# PIC16F1503 register map
Vendor: Microchip
Registers are 8-bit, read-write, no defined reset value unless marked. A register's access mark holds for its fields unless they carry their own. Addresses are absolute, and some are shared; only a register's first bit layout is shown; [hi:lo] are bit positions; {n}, {i} and the like mark numbered series.

## SFR
0x00 INDF0 — (power-on value xxxxxxxx)
0x01 INDF1 — (power-on value xxxxxxxx)
0x02 PCL reset 0x0
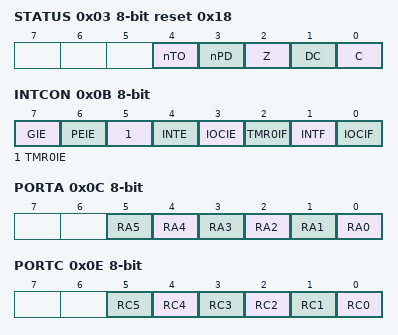
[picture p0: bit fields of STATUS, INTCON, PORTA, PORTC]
0x03 STATUS reset 0x18
  [4] nTO ro, [3] nPD ro, [2] Z, [1] DC, [0] C
0x04 FSR0L reset 0x0
0x05 FSR0H reset 0x0
0x06 FSR1L reset 0x0
0x07 FSR1H reset 0x0
0x08 BSR reset 0x0
  [4:0] BSR
0x09 WREG reset 0x0
  [7:0] WREG0
0x0A PCLATH reset 0x0
  [6:0] PCLATH
0x0B INTCON — (power-on value 0000000x)
  [7] GIE, [6] PEIE, [5] TMR0IE, [4] INTE, [3] IOCIE, [2] TMR0IF, [1] INTF, [0] IOCIF ro
0x0C PORTA — (power-on value --xxxxxx)
  [n] RA{n} (n=0..5)
0x0E PORTC — (power-on value --xxxxxx)
  [n] RC{n} (n=0..5)
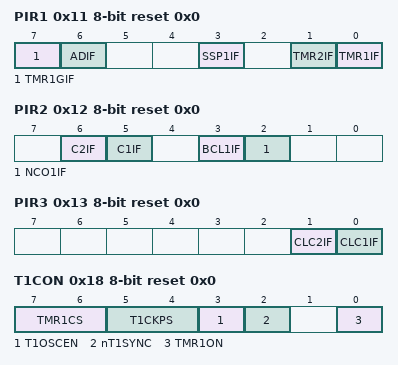
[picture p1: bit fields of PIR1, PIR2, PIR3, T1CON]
0x11 PIR1 reset 0x0
  [7] TMR1GIF — Timer1 Gate Interrupt Flag bit
  [6] ADIF — A/D Converter Interrupt Flag bit
  [3] SSP1IF
  [1] TMR2IF — TMR2 to PR2 Match Interrupt Flag bit
  [0] TMR1IF — TMR1 Overflow Interrupt Flag bit
0x12 PIR2 reset 0x0
  [6] C2IF, [5] C1IF, [3] BCL1IF, [2] NCO1IF
0x13 PIR3 reset 0x0
  [1] CLC2IF, [0] CLC1IF
0x15 TMR0 — (power-on value xxxxxxxx)
0x16 TMR1L — (power-on value xxxxxxxx)
0x17 TMR1H — (power-on value xxxxxxxx)
0x18 T1CON reset 0x0
  [7:6] TMR1CS, [5:4] T1CKPS, [3] T1OSCEN, [2] nT1SYNC, [0] TMR1ON
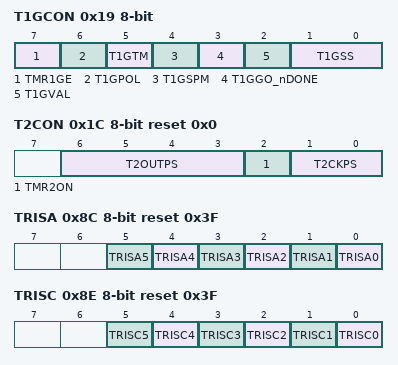
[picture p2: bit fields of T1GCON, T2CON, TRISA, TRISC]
0x19 T1GCON — (power-on value 00000x00)
  [7] TMR1GE, [6] T1GPOL, [5] T1GTM, [4] T1GSPM, [3] T1GGO_nDONE, [2] T1GVAL ro, [1:0] T1GSS
0x1A TMR2 reset 0x0
0x1B PR2 reset 0xFF
0x1C T2CON reset 0x0
  [6:3] T2OUTPS, [2] TMR2ON, [1:0] T2CKPS
0x8C TRISA reset 0x3F — PORTA Data Direction Control Register
  [n] TRISA{n} (n=0..5)
0x8E TRISC reset 0x3F — PORTC Data Direction Control Register
  [n] TRISC{n} (n=0..5)
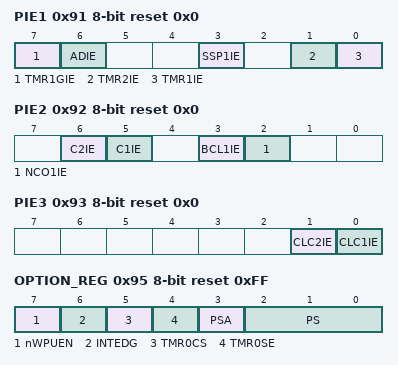
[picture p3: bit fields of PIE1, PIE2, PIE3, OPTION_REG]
0x91 PIE1 reset 0x0 — Peripheral Interrupt Enable Register 1
  [7] TMR1GIE — Timer1 Gate Interrupt Enable bit
  [6] ADIE — A/D Converter Interrupt Enable bit
  [3] SSP1IE
  [1] TMR2IE — TMR2 to PR2 Match Interrupt Enable bit
  [0] TMR1IE — TMR1 Overflow Interrupt Enable bit
0x92 PIE2 reset 0x0 — Peripheral Interrupt Enable Register 2
  [6] C2IE, [5] C1IE, [3] BCL1IE, [2] NCO1IE
0x93 PIE3 reset 0x0 — Peripheral Interrupt Enable Register 3
  [1] CLC2IE, [0] CLC1IE
0x95 OPTION_REG reset 0xFF — Option Register
  [7] nWPUEN — Weak Pull-up Enable bit
  [6] INTEDG — Interrupt Edge Select bit
  [5] TMR0CS
  [4] TMR0SE — TMR0 Source Edge Select bit
  [3] PSA — Prescaler Active bit
  [2:0] PS
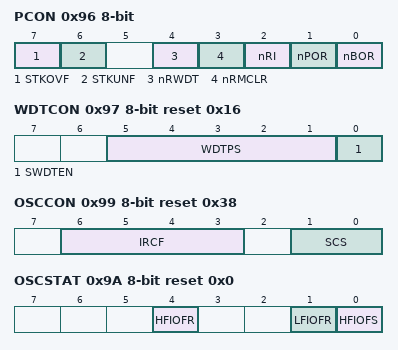
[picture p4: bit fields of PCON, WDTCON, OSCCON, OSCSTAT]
0x96 PCON — Power Control Register (power-on value 00-111qq)
  [7] STKOVF — Stack Overflow Flag bit
  [6] STKUNF — Stack Underflow Flag bit
  [4] nRWDT
  [3] nRMCLR — MCLR Reset Flag bit
  [2] nRI — RESET Instruction Flag bit
  [1] nPOR — Power-on Reset Status bit
  [0] nBOR — Brown-out Reset Status bit
0x97 WDTCON reset 0x16 — Watchdog Timer Control Register
  [5:1] WDTPS
  [0] SWDTEN — Software Enable/Disable for Watch Dog Timer bit
0x99 OSCCON reset 0x38 — Oscillator Control Register
  [6:3] IRCF, [1:0] SCS
0x9A OSCSTAT ro reset 0x0 — Oscillator Status Register
  [4] HFIOFR
  [1] LFIOFR — Low Freqency Internal Oscillator Ready bit
  [0] HFIOFS — Low Freqency Internal Oscillator Ready bit
0x9B ADRESL — A/D Result Register LSB (power-on value xxxxxxxx)
0x9C ADRESH — A/D Result Register MSB (power-on value xxxxxxxx)
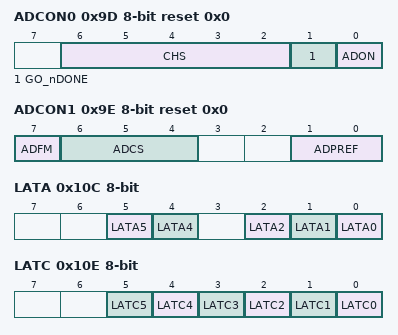
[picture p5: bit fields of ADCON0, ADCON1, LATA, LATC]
0x9D ADCON0 reset 0x0 — Analog-to-Digital Control Register 0
  [6:2] CHS
  [1] GO_nDONE — A/D Conversion Status bit
  [0] ADON — A/D Module Enable bit
0x9E ADCON1 reset 0x0 — Analog-to-Digital Control Register 1
  [7] ADFM — A/D Result Format Select bit
  [6:4] ADCS
  [1:0] ADPREF
0x9F ADCON2 reset 0x0 — Analog-to-Digital Control Register 2
  [7:4] TRIGSEL
0x10C LATA — (power-on value --xx-xxx)
  [5] LATA5, [4] LATA4, [2] LATA2, [1] LATA1, [0] LATA0
0x10E LATC — (power-on value --xxxxxx)
  [n] LATC{n} (n=0..5)
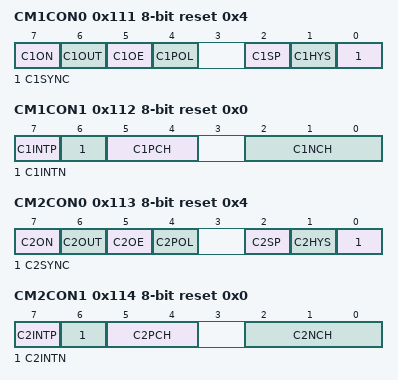
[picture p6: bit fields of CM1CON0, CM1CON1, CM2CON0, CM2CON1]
0x111 CM1CON0 reset 0x4
  [7] C1ON — Comparator Enable bit
  [6] C1OUT ro — Comparator Output bit
  [5] C1OE — Comparator Output Enable bit
  [4] C1POL — Comparator Output Polarity Select bit
  [2] C1SP — Comparator Speed/Power Select bit
  [1] C1HYS — Comparator Hysteresis Enable bit
  [0] C1SYNC — Comparator Output Synchronous Mode bit
0x112 CM1CON1 reset 0x0
  [7] C1INTP — Comparator Interrupt on Positive going edge Enable bits
  [6] C1INTN — Comparator Interrupt on Negative going edge Enable bits
  [5:4] C1PCH
  [2:0] C1NCH
0x113 CM2CON0 reset 0x4
  [7] C2ON, [6] C2OUT ro, [5] C2OE, [4] C2POL, [2] C2SP, [1] C2HYS, [0] C2SYNC
0x114 CM2CON1 reset 0x0
  [7] C2INTP — Comparator Interrupt on Positive going edge Enable bits
  [6] C2INTN — Comparator Interrupt on Negative going edge Enable bits
  [5:4] C2PCH
  [2:0] C2NCH
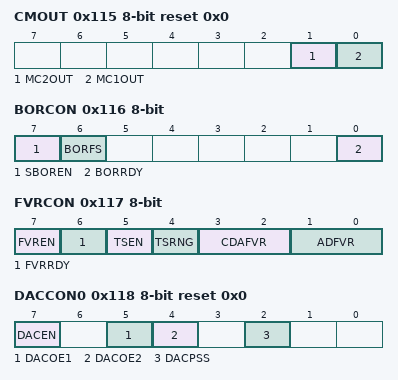
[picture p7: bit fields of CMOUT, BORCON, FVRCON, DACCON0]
0x115 CMOUT ro reset 0x0 — Comparator Output Register
  [1] MC2OUT, [0] MC1OUT
0x116 BORCON — Brown-out Reset Control Register (power-on value 10-----q)
  [7] SBOREN — Software Brown Out Reset Enable bit
  [6] BORFS
  [0] BORRDY ro — Brown-out Reset Circuit Ready Status bit
0x117 FVRCON — Voltage Reference Control Register 0 (power-on value 0q000000)
  [7] FVREN — Fixed Voltage Reference Enable
  [6] FVRRDY ro — Fixed Voltage Reference Ready Flag
  [5] TSEN — Temperature Sensor Enable
  [4] TSRNG — Temperature Sensor Range Select
  [3:2] CDAFVR
  [1:0] ADFVR — A/D Converter Fixed Voltage Reference Selection
0x118 DACCON0 reset 0x0 — Voltage Reference Control Register 0
  [7] DACEN — DAC module enable
  [5] DACOE1 — DAC1 Voltage Output 1 Enable bit
  [4] DACOE2 — DAC1 Voltage Output 2 Enable bit
  [2] DACPSS — DAC1 Positive Source Select bit
0x119 DACCON1 reset 0x0 — Voltage Reference Control Register 1
  [4:0] DACR
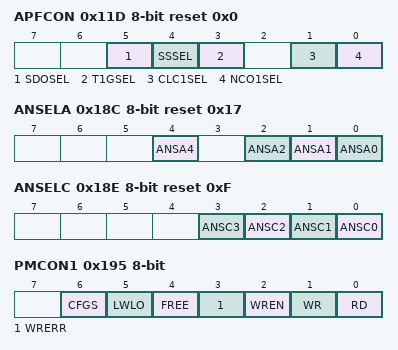
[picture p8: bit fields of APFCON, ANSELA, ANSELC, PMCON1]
0x11D APFCON reset 0x0 — Alternate Pin Function Control Register
  [5] SDOSEL, [4] SSSEL, [3] T1GSEL, [1] CLC1SEL, [0] NCO1SEL
0x18C ANSELA reset 0x17
  [4] ANSA4, [2] ANSA2, [1] ANSA1, [0] ANSA0
0x18E ANSELC reset 0xF
  [n] ANSC{n} (n=0..3)
0x191 PMADRL reset 0x0
0x192 PMADRH reset 0x80
  [6:0] PMADRH
0x193 PMDATL — (power-on value xxxxxxxx)
0x194 PMDATH — (power-on value --xxxxxx)
  [5:0] PMDATH
0x195 PMCON1 — (power-on value 1000x000)
  [6] CFGS — FLASH Program / Configuration Select bit
  [5] LWLO — Load Write Latches Only bit
  [4] FREE — Program FLASH Erase Enable bit
  [3] WRERR — Sequence Error Flag bit
  [2] WREN — Program/Erase Enable bit
  [1] WR — Write Control bit (can only be set)
  [0] RD — Read Control bit (can only be set)
0x196 PMCON2 wo reset 0x0
0x197 VREGCON reset 0x0
  [1] VREGPM
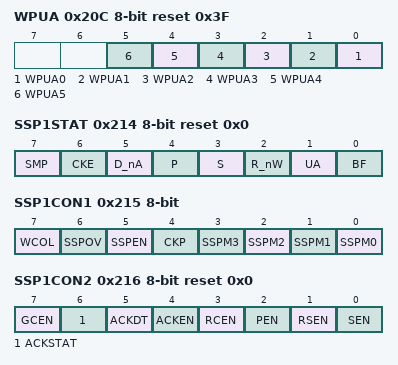
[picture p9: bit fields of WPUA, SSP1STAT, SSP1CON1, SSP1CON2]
0x20C WPUA reset 0x3F
  [n] WPUA{n} (n=0..5)
0x211 SSP1BUF — (power-on value xxxxxxxx)
  [7:0] SSPBUF
0x212 SSP1ADD reset 0x0
  [7:0] ADD
0x213 SSP1MSK reset 0xFF
  [7:0] MSK
0x214 SSP1STAT reset 0x0
  [7] SMP, [6] CKE, [5] D_nA, [4] P, [3] S, [2] R_nW, [1] UA, [0] BF
0x215 SSP1CON1 — (power-on value 0000xxxx)
  [7] WCOL, [6] SSPOV, [5] SSPEN, [4] CKP, [n] SSPM{n} (n=0..3)
0x216 SSP1CON2 reset 0x0
  [7] GCEN, [6] ACKSTAT, [5] ACKDT, [4] ACKEN, [3] RCEN, [2] PEN, [1] RSEN, [0] SEN
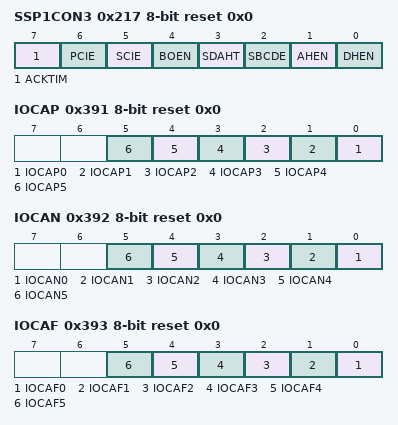
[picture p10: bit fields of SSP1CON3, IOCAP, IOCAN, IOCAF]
0x217 SSP1CON3 reset 0x0
  [7] ACKTIM, [6] PCIE, [5] SCIE, [4] BOEN, [3] SDAHT, [2] SBCDE, [1] AHEN, [0] DHEN
0x391 IOCAP reset 0x0
  [n] IOCAP{n} (n=0..5)
0x392 IOCAN reset 0x0
  [n] IOCAN{n} (n=0..5)
0x393 IOCAF reset 0x0
  [n] IOCAF{n} (n=0..5)
{0x60E+3i} PWM{i}DCL (i=1..4) — (power-on value xx------)
  [7:6] PWM{i}DCL
{0x60F+3i} PWM{i}DCH (i=1..4) — (power-on value xxxxxxxx)
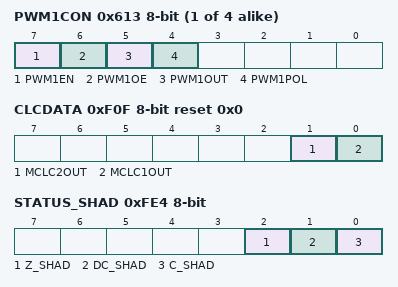
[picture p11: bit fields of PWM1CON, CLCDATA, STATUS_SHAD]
{0x610+3i} PWM{i}CON (i=1..4) — Configurable logic cell control (power-on value 00x0----)
  [7] PWM{i}EN, [6] PWM{i}OE, [5] PWM{i}OUT ro, [4] PWM{i}POL
0xF0F CLCDATA ro reset 0x0
  [1] MCLC2OUT, [0] MCLC1OUT
0xFE3 BSR_ICDSHAD — (power-on value ---xxxxx)
  [4:0] BSR_ICDSHAD
0xFE4 STATUS_SHAD — (power-on value -----xxx)
  [2] Z_SHAD, [1] DC_SHAD, [0] C_SHAD
0xFE5 WREG_SHAD — (power-on value xxxxxxxx)
0xFE6 BSR_SHAD — (power-on value ---xxxxx)
  [4:0] BSR_SHAD
0xFE7 PCLATH_SHAD — (power-on value -xxxxxxx)
  [6:0] PCLATH_SHAD
0xFE8 FSR0L_SHAD — (power-on value xxxxxxxx)
0xFE9 FSR0H_SHAD — (power-on value xxxxxxxx)
0xFEA FSR1L_SHAD — (power-on value xxxxxxxx)
0xFEB FSR1H_SHAD — (power-on value xxxxxxxx)
0xFED STKPTR reset 0x1F — Current Stack pointer
  [4:0] STKPTR
0xFEE TOSL — Top of Stack Low byte (power-on value xxxxxxxx)
0xFEF TOSH — Top of Stack High byte (power-on value -xxxxxxx)
  [6:0] TOSH
